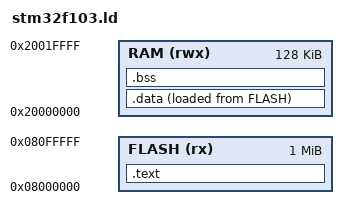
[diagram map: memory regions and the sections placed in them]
/* STM32F103 Linker Script for LabWired Arduino Simulation */
MEMORY
{
    FLASH (rx) : ORIGIN = 0x08000000, LENGTH = 1M
    RAM (rwx)  : ORIGIN = 0x20000000, LENGTH = 128K
}

SECTIONS
{
    .text :
    {
        KEEP(*(.vectors))
        *(.text*)
        *(.rodata*)
    } > FLASH

    .data :
    {
        _sdata = .;
        *(.data*)
        _edata = .;
    } > RAM AT > FLASH

    .bss :
    {
        _sbss = .;
        *(.bss*)
        *(COMMON)
        _ebss = .;
    } > RAM

    _estack = ORIGIN(RAM) + LENGTH(RAM);
}
